VERSION ""

NS_ :

BS_:

BU_: BMS IBC MCU ZCU_Rear
VAL_TABLE_ vtbSensorReqCause 15 "SNA" 2 "by Request 2" 1 "by Request 1" 0 "normal cycle" ;
VAL_TABLE_ vtbErrorDescription 255 "ERROR" ;

BO_ 772 L008_MCU_Control: 3 ZCU_Rear
 SG_ Regen_Mode : 16|3@1+ (1,0) [0|7] ""  MCU
 SG_ Target_Torque : 0|16@1- (0.1,0) [-3200|3200] "Nm"  MCU

BO_ 771 L007_BMS_Detail_Status: 12 Vector__XXX
 SG_ Battery_Voltage : 40|32@1- (1,0) [-3.4E+38|3.4E+38] ""  ZCU_Rear
 SG_ Battery_SoC : 32|8@1+ (1,0) [0|255] ""  ZCU_Rear
 SG_ Battery_Current : 0|32@1- (1,0) [-3.4E+38|3.4E+38] ""  ZCU_Rear

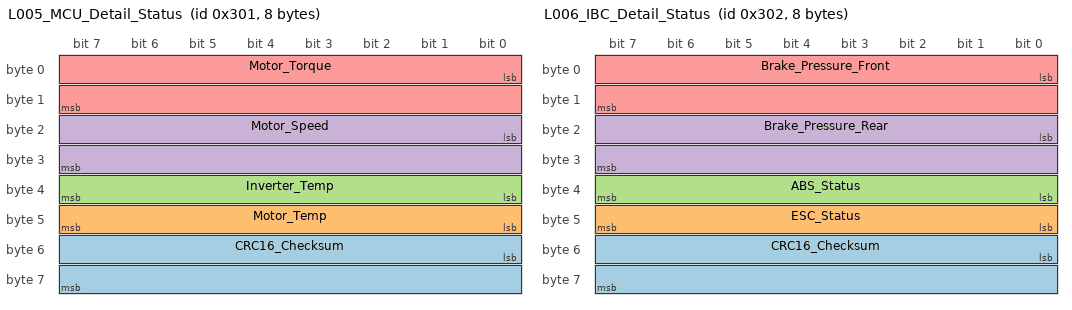
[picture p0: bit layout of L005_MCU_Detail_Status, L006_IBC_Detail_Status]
BO_ 769 L005_MCU_Detail_Status: 8 MCU
 SG_ CRC16_Checksum : 48|16@1+ (1,0) [0|65535] ""  ZCU_Rear
 SG_ Motor_Temp : 40|8@1+ (1,-40) [-40|215] "degC"  ZCU_Rear
 SG_ Inverter_Temp : 32|8@1+ (1,-40) [-40|215] "degC"  ZCU_Rear
 SG_ Motor_Speed : 16|16@1+ (1,0) [0|65535] "rpm"  ZCU_Rear
 SG_ Motor_Torque : 0|16@1- (0.1,0) [-3200|3200] "Nm"  ZCU_Rear

BO_ 770 L006_IBC_Detail_Status: 8 IBC
 SG_ CRC16_Checksum : 48|16@1+ (1,0) [0|65535] ""  ZCU_Rear
 SG_ ESC_Status : 40|8@1+ (1,0) [0|255] ""  ZCU_Rear
 SG_ ABS_Status : 32|8@1+ (1,0) [0|255] ""  ZCU_Rear
 SG_ Brake_Pressure_Rear : 16|16@1+ (0.1,0) [0|6553.5] "bar"  ZCU_Rear
 SG_ Brake_Pressure_Front : 0|16@1+ (0.1,0) [0|6553.5] "bar"  ZCU_Rear

BA_DEF_ BO_  "VFrameFormat" ENUM  "StandardCAN","ExtendedCAN","reserved","reserved","reserved","reserved","reserved","reserved","reserved","reserved","reserved","reserved","reserved","reserved","StandardCAN_FD","ExtendedCAN_FD";
BA_DEF_  "DatabaseVersion" STRING ;
BA_DEF_  "Manufacturer" STRING ;
BA_DEF_ BU_  "NodeLayerModules" STRING ;
BA_DEF_  "BusType" STRING ;
BA_DEF_ SG_  "GenSigSendType" ENUM  "Cyclic","OnWrite","OnWriteWithRepetition","OnChange","OnChangeWithRepetition","IfActive","IfActiveWithRepetition","NoSigSendType","NotUsed","NotUsed","NotUsed","NotUsed","NotUsed";
BA_DEF_ BO_  "GenMsgSendType" ENUM  "Cyclic","NotUsed","NotUsed","NotUsed","NotUsed","Cyclic","NotUsed","IfActive","NoMsgSendType","NotUsed","vector_leerstring";
BA_DEF_ BO_  "GenMsgCycleTime" INT 0 50000;
BA_DEF_ BO_  "GenMsgCycleTimeFast" INT 0 50000;
BA_DEF_ BO_  "GenMsgILSupport" ENUM  "No","Yes";
BA_DEF_DEF_  "VFrameFormat" "ExtendedCAN_FD";
BA_DEF_DEF_  "DatabaseVersion" "";
BA_DEF_DEF_  "Manufacturer" "Vector";
BA_DEF_DEF_  "NodeLayerModules" "CANoeILNLVector.dll";
BA_DEF_DEF_  "BusType" "CAN";
BA_DEF_DEF_  "GenSigSendType" "Cyclic";
BA_DEF_DEF_  "GenMsgSendType" "NoMsgSendType";
BA_DEF_DEF_  "GenMsgCycleTime" 200;
BA_DEF_DEF_  "GenMsgCycleTimeFast" 20;
BA_DEF_DEF_  "GenMsgILSupport" "Yes";
BA_ "BusType" "CAN FD";
BA_ "VFrameFormat" BO_ 772 0;
BA_ "VFrameFormat" BO_ 771 14;
BA_ "GenMsgCycleTime" BO_ 769 10;
BA_ "VFrameFormat" BO_ 769 14;
BA_ "GenMsgCycleTime" BO_ 770 10;
BA_ "VFrameFormat" BO_ 770 14;
SIG_VALTYPE_ 771 Battery_Voltage : 1;
SIG_VALTYPE_ 771 Battery_Current : 1;
